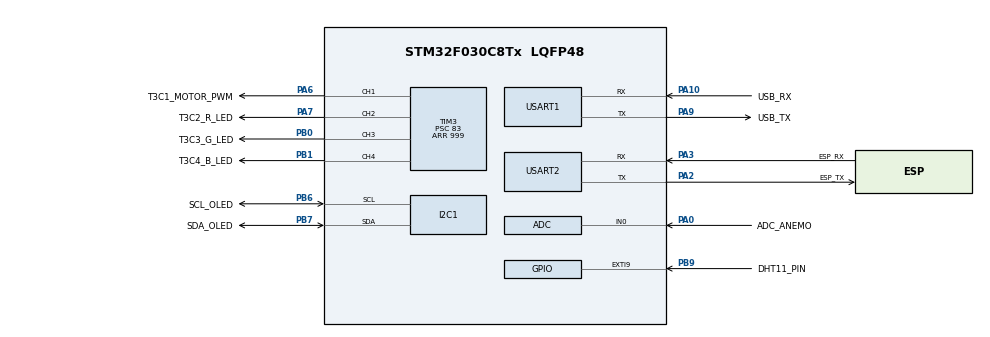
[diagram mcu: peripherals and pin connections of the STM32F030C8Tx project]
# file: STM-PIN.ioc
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I2C1.Timing=0x00201D2B
Mcu.Family=STM32F0
Mcu.Name=STM32F030C8Tx
Mcu.Package=LQFP48
NVIC.ADC1_IRQn=true\:0\:0\:false\:false\:true\:true\:true\:true
NVIC.EXTI4_15_IRQn=true\:0\:0\:false\:false\:true\:true\:true\:true
NVIC.I2C1_IRQn=true\:0\:0\:false\:false\:true\:true\:true\:true
NVIC.RCC_IRQn=true\:0\:0\:false\:false\:true\:true\:false\:true
NVIC.TIM3_IRQn=true\:0\:0\:false\:false\:true\:true\:true\:true
NVIC.USART1_IRQn=true\:0\:0\:false\:false\:true\:true\:true\:true
NVIC.USART2_IRQn=true\:0\:0\:false\:false\:true\:true\:true\:true
PA0.GPIO_Label=ADC_ANEMO
PA0.Mode=IN0
PA0.Signal=ADC_IN0
PA10.GPIO_Label=USB_RX
PA10.Mode=Asynchronous
PA10.Signal=USART1_RX
PA13.Mode=Serial_Wire
PA13.Signal=SYS_SWDIO
PA14.Mode=Serial_Wire
PA14.Signal=SYS_SWCLK
PA2.GPIO_Label=ESP_TX
PA2.Mode=Asynchronous
PA2.Signal=USART2_TX
PA3.GPIO_Label=ESP_RX
PA3.Mode=Asynchronous
PA3.Signal=USART2_RX
PA6.GPIO_Label=T3C1_MOTOR_PWM
PA6.Signal=S_TIM3_CH1
PA7.GPIO_Label=T3C2_R_LED
PA7.Signal=S_TIM3_CH2
PA9.GPIO_Label=USB_TX
PA9.Mode=Asynchronous
PA9.Signal=USART1_TX
PB0.GPIO_Label=T3C3_G_LED
PB0.Signal=S_TIM3_CH3
PB1.GPIO_Label=T3C4_B_LED
PB1.Signal=S_TIM3_CH4
PB6.GPIO_Label=SCL_OLED
PB6.Mode=I2C
PB6.Signal=I2C1_SCL
PB7.GPIO_Label=SDA_OLED
PB7.Mode=I2C
PB7.Signal=I2C1_SDA
PB9.GPIO_Label=DHT11_PIN
PB9.Signal=GPXTI9
ProjectManager.HeapSize=0x200
ProjectManager.StackSize=0x400
ProjectManager.TargetToolchain=CMake
SH.S_TIM3_CH1.0=TIM3_CH1,PWM Generation1 CH1
SH.S_TIM3_CH2.0=TIM3_CH2,PWM Generation2 CH2
SH.S_TIM3_CH3.0=TIM3_CH3,PWM Generation3 CH3
SH.S_TIM3_CH4.0=TIM3_CH4,PWM Generation4 CH4
TIM1.Prescaler=71
TIM3.Channel-PWM\ Generation1\ CH1=TIM_CHANNEL_1
TIM3.Channel-PWM\ Generation2\ CH2=TIM_CHANNEL_2
TIM3.Channel-PWM\ Generation3\ CH3=TIM_CHANNEL_3
TIM3.Channel-PWM\ Generation4\ CH4=TIM_CHANNEL_4
TIM3.Period=999
TIM3.Prescaler=83
USART1.VirtualMode-Asynchronous=VM_ASYNC
USART2.VirtualMode-Asynchronous=VM_ASYNC
VP_TIM1_VS_ClockSourceINT.Mode=Internal
VP_TIM3_VS_ClockSourceINT.Mode=Internal
VP_TIM3_VS_ClockSourceITR.Mode=TriggerSource_ITR0
board=custom

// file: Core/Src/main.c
/* USER CODE BEGIN Header */
/**
  ******************************************************************************
  * @file           : main.c
  * @brief          : Main program body
  ******************************************************************************
  * @attention
  *
  * Copyright (c) 2025 STMicroelectronics.
  * All rights reserved.
  *
  * This software is licensed under terms that can be found in the LICENSE file
  * in the root directory of this software component.
  * If no LICENSE file comes with this software, it is provided AS-IS.
  *
  ******************************************************************************
  */
/* USER CODE END Header */
#include "main.h"

ADC_HandleTypeDef hadc;

I2C_HandleTypeDef hi2c1;

TIM_HandleTypeDef htim1;
TIM_HandleTypeDef htim3;

UART_HandleTypeDef huart1;
UART_HandleTypeDef huart2;

void SystemClock_Config(void);
static void MX_GPIO_Init(void);
static void MX_ADC_Init(void);
static void MX_I2C1_Init(void);
static void MX_TIM3_Init(void);
static void MX_USART1_UART_Init(void);
static void MX_USART2_UART_Init(void);
static void MX_TIM1_Init(void);

/* USER CODE BEGIN 0 */
/**
  * @brief  Cambia el duty cycle de un canal PWM del TIM3.
  * @param  htim: Puntero al manejador (handle) del TIM3.
  * @param  Channel: Canal del TIM3 a configurar (ej. TIM_CHANNEL_1, TIM_CHANNEL_2, etc.).
  * @param  DutyCycle_Percentage: Valor del duty cycle en porcentaje (0 a 100).
  * @retval None
  */
void Set_PWM_DutyCycle(TIM_HandleTypeDef *htim, uint32_t Channel, float DutyCycle_Percentage)
{
    // Asegurarse de que el porcentaje esté dentro del rango válido (0-100)
    if (DutyCycle_Percentage < 0.0f) {
        DutyCycle_Percentage = 0.0f;
    } else if (DutyCycle_Percentage > 100.0f) {
        DutyCycle_Percentage = 100.0f;
    }

    // Calcular el valor del "Pulse" basado en el porcentaje y el periodo del timer
    // htim->Init.Period contiene el valor de ARR (Auto-Reload Register) - 1.
    // El periodo real del contador es (htim->Init.Period + 1).
    // Sin embargo, para el cálculo del CCRx, se usa directamente htim->Init.Period
    // como el valor máximo para 100% de duty cycle, o (htim->Init.Period + 1) si estás usando la configuración
    // del timer para que el ARR se cuente como el último valor.
    // Para la mayoría de las configuraciones típicas en STM32, Period es el valor máximo para CCRx.
    uint32_t pulse_value = (uint32_t)((DutyCycle_Percentage / 100.0f) * htim->Init.Period);

    // Actualizar el registro de comparación del canal PWM
    __HAL_TIM_SET_COMPARE(htim, Channel, pulse_value);
}

/* USER CODE END 0 */

int main(void)
{

  /* MCU Configuration--------------------------------------------------------*/

  /* Reset of all peripherals, Initializes the Flash interface and the Systick. */
  HAL_Init();

  /* Configure the system clock */
  SystemClock_Config();

  /* Initialize all configured peripherals */
  MX_GPIO_Init();
  MX_ADC_Init();
  MX_I2C1_Init();
  MX_TIM3_Init();
  MX_USART1_UART_Init();
  MX_USART2_UART_Init();
  MX_TIM1_Init();

  /* Infinite loop */
  while (1)
  {

  }
}

void SystemClock_Config(void)
{
  RCC_OscInitTypeDef RCC_OscInitStruct = {0};
  RCC_ClkInitTypeDef RCC_ClkInitStruct = {0};
  RCC_PeriphCLKInitTypeDef PeriphClkInit = {0};

  /** Initializes the RCC Oscillators according to the specified parameters
  * in the RCC_OscInitTypeDef structure.
  */
  RCC_OscInitStruct.OscillatorType = RCC_OSCILLATORTYPE_HSI|RCC_OSCILLATORTYPE_HSI14;
  RCC_OscInitStruct.HSIState = RCC_HSI_ON;
  RCC_OscInitStruct.HSI14State = RCC_HSI14_ON;
  RCC_OscInitStruct.HSICalibrationValue = RCC_HSICALIBRATION_DEFAULT;
  RCC_OscInitStruct.HSI14CalibrationValue = 16;
  RCC_OscInitStruct.PLL.PLLState = RCC_PLL_NONE;
  if (HAL_RCC_OscConfig(&RCC_OscInitStruct) != HAL_OK)
  {
    Error_Handler();
  }

  /** Initializes the CPU, AHB and APB buses clocks
  */
  RCC_ClkInitStruct.ClockType = RCC_CLOCKTYPE_HCLK|RCC_CLOCKTYPE_SYSCLK
                              |RCC_CLOCKTYPE_PCLK1;
  RCC_ClkInitStruct.SYSCLKSource = RCC_SYSCLKSOURCE_HSI;
  RCC_ClkInitStruct.AHBCLKDivider = RCC_SYSCLK_DIV1;
  RCC_ClkInitStruct.APB1CLKDivider = RCC_HCLK_DIV1;

  if (HAL_RCC_ClockConfig(&RCC_ClkInitStruct, FLASH_LATENCY_0) != HAL_OK)
  {
    Error_Handler();
  }
  PeriphClkInit.PeriphClockSelection = RCC_PERIPHCLK_USART1|RCC_PERIPHCLK_I2C1;
  PeriphClkInit.Usart1ClockSelection = RCC_USART1CLKSOURCE_PCLK1;
  PeriphClkInit.I2c1ClockSelection = RCC_I2C1CLKSOURCE_HSI;
  if (HAL_RCCEx_PeriphCLKConfig(&PeriphClkInit) != HAL_OK)
  {
    Error_Handler();
  }
}

static void MX_ADC_Init(void)
{

  ADC_ChannelConfTypeDef sConfig = {0};

  /** Configure the global features of the ADC (Clock, Resolution, Data Alignment and number of conversion)
  */
  hadc.Instance = ADC1;
  hadc.Init.ClockPrescaler = ADC_CLOCK_ASYNC_DIV1;
  hadc.Init.Resolution = ADC_RESOLUTION_12B;
  hadc.Init.DataAlign = ADC_DATAALIGN_RIGHT;
  hadc.Init.ScanConvMode = ADC_SCAN_DIRECTION_FORWARD;
  hadc.Init.EOCSelection = ADC_EOC_SINGLE_CONV;
  hadc.Init.LowPowerAutoWait = DISABLE;
  hadc.Init.LowPowerAutoPowerOff = DISABLE;
  hadc.Init.ContinuousConvMode = DISABLE;
  hadc.Init.DiscontinuousConvMode = DISABLE;
  hadc.Init.ExternalTrigConv = ADC_SOFTWARE_START;
  hadc.Init.ExternalTrigConvEdge = ADC_EXTERNALTRIGCONVEDGE_NONE;
  hadc.Init.DMAContinuousRequests = DISABLE;
  hadc.Init.Overrun = ADC_OVR_DATA_PRESERVED;
  if (HAL_ADC_Init(&hadc) != HAL_OK)
  {
    Error_Handler();
  }

  /** Configure for the selected ADC regular channel to be converted.
  */
  sConfig.Channel = ADC_CHANNEL_0;
  sConfig.Rank = ADC_RANK_CHANNEL_NUMBER;
  sConfig.SamplingTime = ADC_SAMPLETIME_1CYCLE_5;
  if (HAL_ADC_ConfigChannel(&hadc, &sConfig) != HAL_OK)
  {
    Error_Handler();
  }

}

static void MX_I2C1_Init(void)
{

  hi2c1.Instance = I2C1;
  hi2c1.Init.Timing = 0x00201D2B;
  hi2c1.Init.OwnAddress1 = 0;
  hi2c1.Init.AddressingMode = I2C_ADDRESSINGMODE_7BIT;
  hi2c1.Init.DualAddressMode = I2C_DUALADDRESS_DISABLE;
  hi2c1.Init.OwnAddress2 = 0;
  hi2c1.Init.OwnAddress2Masks = I2C_OA2_NOMASK;
  hi2c1.Init.GeneralCallMode = I2C_GENERALCALL_DISABLE;
  hi2c1.Init.NoStretchMode = I2C_NOSTRETCH_DISABLE;
  if (HAL_I2C_Init(&hi2c1) != HAL_OK)
  {
    Error_Handler();
  }

  /** Configure Analogue filter
  */
  if (HAL_I2CEx_ConfigAnalogFilter(&hi2c1, I2C_ANALOGFILTER_ENABLE) != HAL_OK)
  {
    Error_Handler();
  }

  /** Configure Digital filter
  */
  if (HAL_I2CEx_ConfigDigitalFilter(&hi2c1, 0) != HAL_OK)
  {
    Error_Handler();
  }

}

static void MX_TIM1_Init(void)
{

  TIM_ClockConfigTypeDef sClockSourceConfig = {0};
  TIM_MasterConfigTypeDef sMasterConfig = {0};

  htim1.Instance = TIM1;
  htim1.Init.Prescaler = 71;
  htim1.Init.CounterMode = TIM_COUNTERMODE_UP;
  htim1.Init.Period = 65535;
  htim1.Init.ClockDivision = TIM_CLOCKDIVISION_DIV1;
  htim1.Init.RepetitionCounter = 0;
  htim1.Init.AutoReloadPreload = TIM_AUTORELOAD_PRELOAD_DISABLE;
  if (HAL_TIM_Base_Init(&htim1) != HAL_OK)
  {
    Error_Handler();
  }
  sClockSourceConfig.ClockSource = TIM_CLOCKSOURCE_INTERNAL;
  if (HAL_TIM_ConfigClockSource(&htim1, &sClockSourceConfig) != HAL_OK)
  {
    Error_Handler();
  }
  sMasterConfig.MasterOutputTrigger = TIM_TRGO_RESET;
  sMasterConfig.MasterSlaveMode = TIM_MASTERSLAVEMODE_DISABLE;
  if (HAL_TIMEx_MasterConfigSynchronization(&htim1, &sMasterConfig) != HAL_OK)
  {
    Error_Handler();
  }

}

static void MX_TIM3_Init(void)
{

  TIM_ClockConfigTypeDef sClockSourceConfig = {0};
  TIM_SlaveConfigTypeDef sSlaveConfig = {0};
  TIM_MasterConfigTypeDef sMasterConfig = {0};
  TIM_OC_InitTypeDef sConfigOC = {0};

  htim3.Instance = TIM3;
  htim3.Init.Prescaler = 83;
  htim3.Init.CounterMode = TIM_COUNTERMODE_UP;
  htim3.Init.Period = 999;
  htim3.Init.ClockDivision = TIM_CLOCKDIVISION_DIV1;
  htim3.Init.AutoReloadPreload = TIM_AUTORELOAD_PRELOAD_DISABLE;
  if (HAL_TIM_Base_Init(&htim3) != HAL_OK)
  {
    Error_Handler();
  }
  sClockSourceConfig.ClockSource = TIM_CLOCKSOURCE_INTERNAL;
  if (HAL_TIM_ConfigClockSource(&htim3, &sClockSourceConfig) != HAL_OK)
  {
    Error_Handler();
  }
  if (HAL_TIM_PWM_Init(&htim3) != HAL_OK)
  {
    Error_Handler();
  }
  sSlaveConfig.SlaveMode = TIM_SLAVEMODE_DISABLE;
  sSlaveConfig.InputTrigger = TIM_TS_ITR0;
  if (HAL_TIM_SlaveConfigSynchro(&htim3, &sSlaveConfig) != HAL_OK)
  {
    Error_Handler();
  }
  sMasterConfig.MasterOutputTrigger = TIM_TRGO_RESET;
  sMasterConfig.MasterSlaveMode = TIM_MASTERSLAVEMODE_DISABLE;
  if (HAL_TIMEx_MasterConfigSynchronization(&htim3, &sMasterConfig) != HAL_OK)
  {
    Error_Handler();
  }
  sConfigOC.OCMode = TIM_OCMODE_PWM1;
  sConfigOC.Pulse = 0;
  sConfigOC.OCPolarity = TIM_OCPOLARITY_HIGH;
  sConfigOC.OCFastMode = TIM_OCFAST_DISABLE;
  if (HAL_TIM_PWM_ConfigChannel(&htim3, &sConfigOC, TIM_CHANNEL_1) != HAL_OK)
  {
    Error_Handler();
  }
  if (HAL_TIM_PWM_ConfigChannel(&htim3, &sConfigOC, TIM_CHANNEL_2) != HAL_OK)
  {
    Error_Handler();
  }
  if (HAL_TIM_PWM_ConfigChannel(&htim3, &sConfigOC, TIM_CHANNEL_3) != HAL_OK)
  {
    Error_Handler();
  }
  if (HAL_TIM_PWM_ConfigChannel(&htim3, &sConfigOC, TIM_CHANNEL_4) != HAL_OK)
  {
    Error_Handler();
  }
  HAL_TIM_MspPostInit(&htim3);

}

static void MX_USART1_UART_Init(void)
{

  huart1.Instance = USART1;
  huart1.Init.BaudRate = 38400;
  huart1.Init.WordLength = UART_WORDLENGTH_8B;
  huart1.Init.StopBits = UART_STOPBITS_1;
  huart1.Init.Parity = UART_PARITY_NONE;
  huart1.Init.Mode = UART_MODE_TX_RX;
  huart1.Init.HwFlowCtl = UART_HWCONTROL_NONE;
  huart1.Init.OverSampling = UART_OVERSAMPLING_16;
  huart1.Init.OneBitSampling = UART_ONE_BIT_SAMPLE_DISABLE;
  huart1.AdvancedInit.AdvFeatureInit = UART_ADVFEATURE_NO_INIT;
  if (HAL_UART_Init(&huart1) != HAL_OK)
  {
    Error_Handler();
  }

}

static void MX_USART2_UART_Init(void)
{

  huart2.Instance = USART2;
  huart2.Init.BaudRate = 38400;
  huart2.Init.WordLength = UART_WORDLENGTH_8B;
  huart2.Init.StopBits = UART_STOPBITS_1;
  huart2.Init.Parity = UART_PARITY_NONE;
  huart2.Init.Mode = UART_MODE_TX_RX;
  huart2.Init.HwFlowCtl = UART_HWCONTROL_NONE;
  huart2.Init.OverSampling = UART_OVERSAMPLING_16;
  huart2.Init.OneBitSampling = UART_ONE_BIT_SAMPLE_DISABLE;
  huart2.AdvancedInit.AdvFeatureInit = UART_ADVFEATURE_NO_INIT;
  if (HAL_UART_Init(&huart2) != HAL_OK)
  {
    Error_Handler();
  }

}

static void MX_GPIO_Init(void)
{
  GPIO_InitTypeDef GPIO_InitStruct = {0};

  /* GPIO Ports Clock Enable */
  __HAL_RCC_GPIOA_CLK_ENABLE();
  __HAL_RCC_GPIOB_CLK_ENABLE();

  /*Configure GPIO pin : DHT11_PIN_Pin */
  GPIO_InitStruct.Pin = DHT11_PIN_Pin;
  GPIO_InitStruct.Mode = GPIO_MODE_IT_RISING;
  GPIO_InitStruct.Pull = GPIO_NOPULL;
  HAL_GPIO_Init(DHT11_PIN_GPIO_Port, &GPIO_InitStruct);

  /* EXTI interrupt init*/
  HAL_NVIC_SetPriority(EXTI4_15_IRQn, 0, 0);
  HAL_NVIC_EnableIRQ(EXTI4_15_IRQn);

}

void Error_Handler(void)
{
  __disable_irq();
  while (1)
  {
  }
}
